# SYNCBOX_ICONT1_ICONT register map
Vendor: Texas Instruments
Peripheral module from a debugger description file (folder DRA74xP_75xP_76xP_77xP).
Registers are 32-bit, access per field, reset 0x0 unless marked. A register's access mark holds for its fields unless they carry their own. Offsets are as the file gives them; lines under a group give offsets from that group; [hi:lo] are bit positions; {n}, {i} and the like mark numbered series; 'fields as' and 'values as' point back to an identical list; <NAME> marks a mode.

## SYNCBOX_ICONT1_ICONT
0x00 SYNCBOX_REVISION ro reset not defined — IP revision identifier
  [31:0] REVISION — IP revision
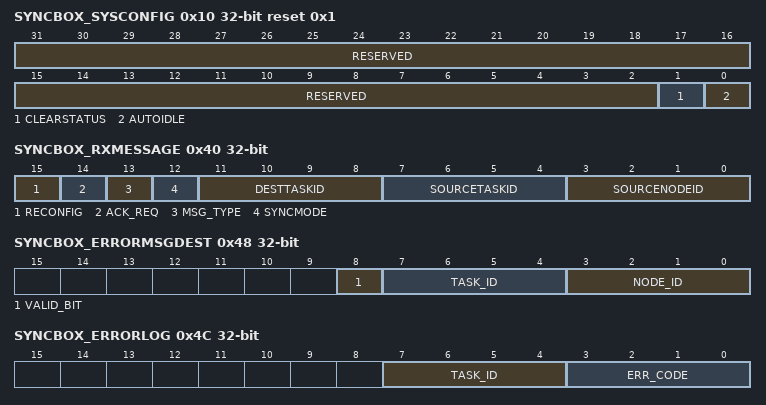
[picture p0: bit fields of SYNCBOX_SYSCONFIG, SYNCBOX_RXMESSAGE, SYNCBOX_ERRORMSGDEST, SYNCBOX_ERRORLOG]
0x10 SYNCBOX_SYSCONFIG reset 0x1 — This register allows controlling various parameters of the OCP interface.
  [31:2] RESERVED ro — Read returns 0.
  [1] CLEARSTATUS rw — Set to 1 to clear dynamic registers
    0=Clear_status_done,_no_pending_action; 0=No_action; 1=Initiate_Clear_status; 1=Clear_status_ongoing
  [0] AUTOIDLE rw — Internal OCP clock gating strategy:
    0=OCP_clock_is_free-running; 1=OCP_OCP_1 (Automatic OCP clock-gating strategy is applied based on the OCP interface activity.)
0x40 SYNCBOX_RXMESSAGE — Register containing the received message, from the CTL_IN interface or MSG_IN interface
  [15] RECONFIG wo — Bit to allow dynamic reconfiguration – not used
  [14] ACK_REQ wo — Bit set to 1 in input message if an acknowledge message must be returned.
  [13] MSG_TYPE wo — Message type 0: Acknowledge message 1: Activation message
  [12] SYNCMODE wo — Synchronous message type: 0 Synchronous 1: Asynchronous
  [11:8] DESTTASKID wo — Task identifier of the destination node
  [7:4] SOURCETASKID wo — Task identifier of the message sender
  [3:0] SOURCENODEID wo — Node identifier of the message sender
0x44 SYNCBOX_NODEIDENTIFIER ro reset not defined — Contains the node identifier. Initialized by default to the tie-off value.
  [3:0] VALUE — Node identifier value
0x48 SYNCBOX_ERRORMSGDEST — Register containing the node and task identifier to send an activation message when an error is detected
  [8] VALID_BIT rw — Validity bit use to send or not the error message to a CPU based node
  [7:4] TASK_ID rw — Identifier for the task in charge of recovering error
  [3:0] NODE_ID rw — Identifier for the node in charge of recovering error
0x4C SYNCBOX_ERRORLOG — Contains the different errors latched during message decoding. Any write to the register resets the current value.
  [7:4] TASK_ID rw — Identifier of the task (or event line) to which error is attached.
  [3:0] ERR_CODE rw — 4 bits coding the error code
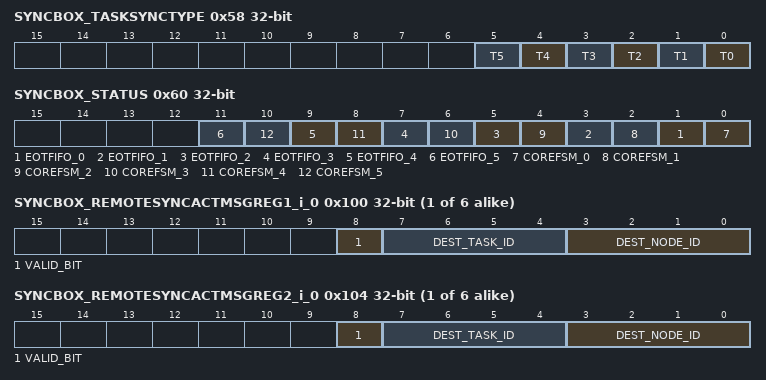
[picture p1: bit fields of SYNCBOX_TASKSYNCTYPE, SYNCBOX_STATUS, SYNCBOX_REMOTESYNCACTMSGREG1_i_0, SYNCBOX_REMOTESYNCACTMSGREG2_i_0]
0x58 SYNCBOX_TASKSYNCTYPE — This register is used to code the task synchronous type: Bit = 0: Synchronous task; Bit = 1: Asynchronous task
  [all] fields
    0=Synchronous_task; 1=Asynchronous_task
  [n] T{n} rw (n=0..5) — Task synchronous or asynchronous
0x60 SYNCBOX_STATUS ro
  [2n+1] EOTFIFO_{n} (n=0..5) — EndOfTask FIFO empty (0) or not empty (1)
  [2n] COREFSM_{n} (n=0..5) — Status bit for task {n}
{0x100+0x80*i} SYNCBOX_REMOTESYNCACTMSGREG1_i_{i} (i=0..5) — Contains destination task identifier and destination node identifier for activation messages to be sent upon task completion. Valid bit is used to loop on all registers of the bundle.
  [8] VALID_BIT rw — Validity bit of current register content: If set to 0, the two fields dest_node_id and dest_task_id can be ignored; if set to 1, the two fields dest_node_id and dest_task_id are used to send activation message.
  [7:4] DEST_TASK_ID rw — Destination task identifier telling at which task in the destination node the activation message must be sent upon task completion
  [3:0] DEST_NODE_ID rw — Destination node identifier
{0x104+0x80*i} SYNCBOX_REMOTESYNCACTMSGREG2_i_{i} (i=0..5) — Contains destination task identifier and destination node identifier for activation messages to be sent upon task completion. Valid bit is used to loop on all registers of the bundle.
  [8] VALID_BIT rw — Validity bit of current register content: If set to 0, the two fields dest_node_id and dest_task_id can be ignored; if f set to 1, the two fields dest_node_id and dest_task_id are used to send activation message.
  [7:4] DEST_TASK_ID rw — Destination task identifier telling at which task in the destination node the activation message must be sent upon task completion
  [3:0] DEST_NODE_ID rw — Destination node identifier
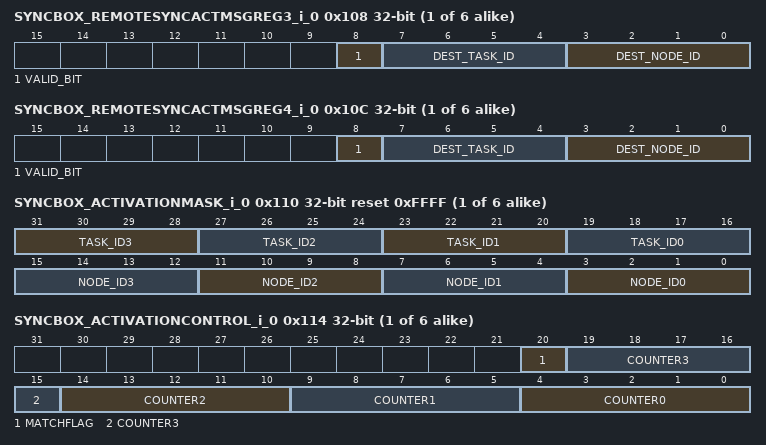
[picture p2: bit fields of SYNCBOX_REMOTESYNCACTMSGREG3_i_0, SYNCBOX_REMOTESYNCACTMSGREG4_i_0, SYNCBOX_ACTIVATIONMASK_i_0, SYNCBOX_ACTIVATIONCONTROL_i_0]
{0x108+0x80*i} SYNCBOX_REMOTESYNCACTMSGREG3_i_{i} (i=0..5) — Contains destination task identifier and destination node identifier for activation messages to be sent upon task completion. Valid bit is used to loop on all registers of the bundle.
  [8] VALID_BIT rw — Validity bit of current register content: If set to 0, the two fields dest_node_id and dest_task_id can be ignored; if set to 1, the two fields dest_node_id and dest_task_id are used to send activation message
  [7:4] DEST_TASK_ID rw — Destination task identifier telling at which task in destination node the activation message must be sent upon task completion
  [3:0] DEST_NODE_ID rw — Destination node identifier
{0x10C+0x80*i} SYNCBOX_REMOTESYNCACTMSGREG4_i_{i} (i=0..5) — Contains destination task identifier and destination node identifier for activation messages to be sent upon task completion. Valid bit is used to loop on all registers of the bundle
  fields as SYNCBOX_REMOTESYNCACTMSGREG1_i_0
{0x110+0x80*i} SYNCBOX_ACTIVATIONMASK_i_{i} rw reset 0xFFFF (i=0..5) — Applies for synchronous task description of bit fields given below. For asynchronous task, only the 16 LSBs are used. Each of the 16 LSBs corresponds to a 1 hot encoding value for the node identifier. 16 MSBs write access is protected by the corresponding bit in the register.
  [31:28] TASK_ID3 — For synchronous message: Each quad bit contains the task ID of a potential activator for asynchronous message. This quad bit contains the task ID to which the ack message must be sent at end of processing.
  [27:24] TASK_ID2 — For synchronous message: Each quad bit contains the task ID of a potential activator for asynchronous message. This quad bit contains the node ID to which the ack message must be sent at end of processing.
  [23:20] TASK_ID1 — For synchronous message: Each quad bit contains the task ID of a potential activator for asynchronous message. This quad bit contains the task ID to which the ack message must be sent at end of processing.
  [19:16] TASK_ID0 — For synchronous message: Each quad bit contains the task ID of a potential activator for asynchronous message. This quad bit contains the node ID to which the ack message must be sent at end of processing.
  [4n+3:4n] NODE_ID{n} (n=0..3) — For synchronous message: Each quad bit contains the node ID of a potential activator for asynchronous message. Bit i set to 1 means an activation message is awaited from node i.
{0x114+0x80*i} SYNCBOX_ACTIVATIONCONTROL_i_{i} ro (i=0..5) — Contains the four activation counters
  [20] MATCHFLAG — Bit set to 1 when all activation messages received
  [19:15] COUNTER3 — Associated counter with the fourth activator
  [14:10] COUNTER2 — Associated counter with the third activator
  [9:5] COUNTER1 — Associated counter with the second activator
  [4:0] COUNTER0 — Associated counter with the first activator
{0x118+0x80*i} SYNCBOX_NEWTASKCOUNTER_i_{i} ro (i=0..5) — NewTask counter
  [12:0] VALUE — Counter of the number of times the NewTask signal has been activated. Caution:This is not a macroblock counter because N MB can be processed every call.
